# ESP32-S2 register map
Vendor: ESPRESSIF SYSTEMS (SHANGHAI) CO., LTD.; Series: ESP32 S-Series; File version: 20
CPU: Xtensa LX7 r0p0, little endian, no MPU, no FPU, 0 interrupt priority bits
Address unit: 32 bits
Registers are 32-bit, read-write, reset 0x0 unless marked. A register's access mark holds for its fields unless they carry their own. Offsets are from the block's base; [hi:lo] are bit positions; {n}, {i} and the like mark numbered series.

## SPI2 — SPI (Serial Peripheral Interface) Controller 2 (GPSPI)
Base 0x3F424000
Same registers: SPI3 0x3F425000, SPI4 0x3F437000
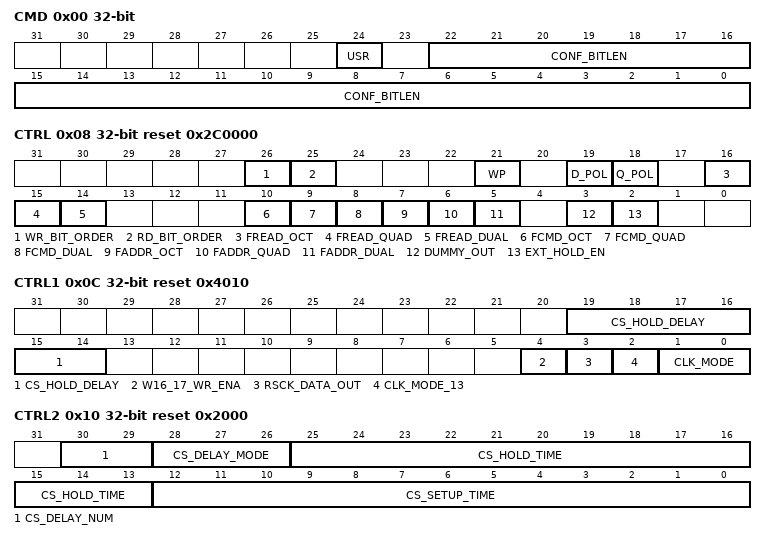
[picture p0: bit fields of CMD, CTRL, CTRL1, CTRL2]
0x00 CMD — Command control register
  [24] USR — User define command enable. An operation will be triggered when the bit is set. The bit will be cleared once the operation done.1: enable 0: disable. Can not be changed by CONF_buf.
  [22:0] CONF_BITLEN — Define the spi_clk cycles of SPI_CONF state. Can be configured in CONF state.
0x04 ADDR — Address value
  [31:0] USR_ADDR_VALUE — [31:8]:address to slave, [7:0]:Reserved. Can be configured in CONF state.
0x08 CTRL reset 0x2C0000 — SPI control register
  [26] WR_BIT_ORDER — In command address write-data (MOSI) phases 1: LSB firs 0: MSB first. Can be configured in CONF state.
  [25] RD_BIT_ORDER — In read-data (MISO) phase 1: LSB first 0: MSB first. Can be configured in CONF state.
  [21] WP — Write protect signal output when SPI is idle. 1: output high, 0: output low. Can be configured in CONF state.
  [19] D_POL — The bit is used to set MOSI line polarity, 1: high 0, low. Can be configured in CONF state.
  [18] Q_POL — The bit is used to set MISO line polarity, 1: high 0, low. Can be configured in CONF state.
  [16] FREAD_OCT — In the read operations read-data phase is in 8-bit mode. 1: enable 0: disable. Can be configured in CONF state.
  [15] FREAD_QUAD — In the read operations read-data phase is in 4-bit mode. 1: enable 0: disable. Can be configured in CONF state.
  [14] FREAD_DUAL — In the read operations, read-data phase is in 2-bit mode. 1: enable 0: disable. Can be configured in CONF state.
  [10] FCMD_OCT — Apply 8-bit mode during command phase 1:enable 0: disable. Can be configured in CONF state.
  [9] FCMD_QUAD — Apply 4-bit mode during command phase 1:enable 0: disable. Can be configured in CONF state.
  [8] FCMD_DUAL — Apply 2-bit mode during command phase 1:enable 0: disable. Can be configured in CONF state.
  [7] FADDR_OCT — Apply 8-bit mode during addr phase 1:enable 0: disable. Can be configured in CONF state.
  [6] FADDR_QUAD — Apply 4-bit mode during addr phase 1:enable 0: disable. Can be configured in CONF state.
  [5] FADDR_DUAL — Apply 2-bit mode during addr phase 1:enable 0: disable. Can be configured in CONF state.
  [3] DUMMY_OUT — In the dummy phase the signal level of spi is output by the spi controller. Can be configured in CONF state.
  [2] EXT_HOLD_EN — Set the bit to hold spi. The bit is combined with SPI_USR_PREP_HOLD,SPI_USR_CMD_HOLD,SPI_USR_ADDR_HOLD,SPI_USR_DUMMY_HOLD,SPI_USR_DIN_HOLD,SPI_USR_DOUT_HOLD and SPI_USR_HOLD_POL. Can be configured in CONF state.
0x0C CTRL1 reset 0x4010 — SPI control register 1
  [19:14] CS_HOLD_DELAY — SPI cs signal is delayed by spi clock cycles. Can be configured in CONF state.
  [4] W16_17_WR_ENA — 1:SPI_BUF16~SPI_BUF17 can be written 0:SPI_BUF16~SPI_BUF17 can not be written. Can be configured in CONF state.
  [3] RSCK_DATA_OUT — It saves half a cycle when tsck is the same as rsck. 1: output data at rsck posedge 0: output data at tsck posedge
  [2] CLK_MODE_13 — {CPOL, CPHA},1: support spi clk mode 1 and 3, first edge output data B[0]/B[7]. 0: support spi clk mode 0 and 2, first edge output data B[1]/B[6].
  [1:0] CLK_MODE — SPI clock mode bits. 0: SPI clock is off when CS inactive 1: SPI clock is delayed one cycle after CS inactive 2: SPI clock is delayed two cycles after CS inactive 3: SPI clock is alwasy on. Can be configured in CONF state.
0x10 CTRL2 reset 0x2000 — SPI control register 2
  [30:29] CS_DELAY_NUM — spi_cs signal is delayed by system clock cycles. Can be configured in CONF state.
  [28:26] CS_DELAY_MODE — spi_cs signal is delayed by spi_clk . 0: zero 1: if SPI_CK_OUT_EDGE or SPI_CK_IDLE_EDGE is set 1 delayed by half cycle else delayed by one cycle 2: if SPI_CK_OUT_EDGE or SPI_CK_IDLE_EDGE is set 1 delayed by one cycle, else delayed by half cycle 3: delayed one cycle. Can be configured in CONF state.
  [25:13] CS_HOLD_TIME — delay cycles of cs pin by spi clock this bits are combined with SPI_CS_HOLD bit. Can be configured in CONF state.
  [12:0] CS_SETUP_TIME — (cycles+1) of prepare phase by spi clock this bits are combined with SPI_CS_SETUP bit. Can be configured in CONF state.
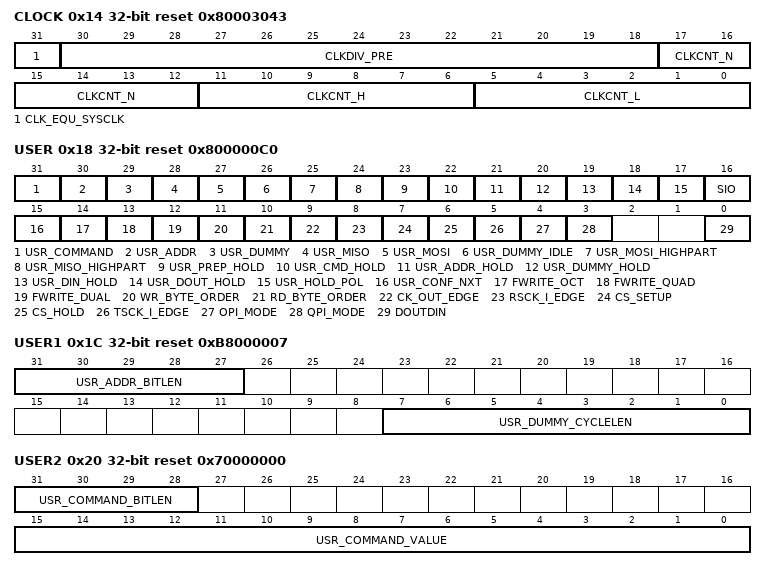
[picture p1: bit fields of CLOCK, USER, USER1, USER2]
0x14 CLOCK reset 0x80003043 — SPI clock control register
  [31] CLK_EQU_SYSCLK — In the master mode 1: spi_clk is eqaul to system 0: spi_clk is divided from system clock. Can be configured in CONF state.
  [30:18] CLKDIV_PRE — In the master mode it is pre-divider of spi_clk. Can be configured in CONF state.
  [17:12] CLKCNT_N — In the master mode it is the divider of spi_clk. So spi_clk frequency is system/(SPI_CLKDIV_PRE+1)/(SPI_CLKCNT_N+1). Can be configured in CONF state.
  [11:6] CLKCNT_H — In the master mode it must be floor((SPI_CLKCNT_N+1)/2-1). In the slave mode it must be 0. Can be configured in CONF state.
  [5:0] CLKCNT_L — In the master mode it must be equal to SPI_CLKCNT_N. In the slave mode it must be 0. Can be configured in CONF state.
0x18 USER reset 0x800000C0 — SPI USER control register
  [31] USR_COMMAND — This bit enable the command phase of an operation. Can be configured in CONF state.
  [30] USR_ADDR — This bit enable the address phase of an operation. Can be configured in CONF state.
  [29] USR_DUMMY — This bit enable the dummy phase of an operation. Can be configured in CONF state.
  [28] USR_MISO — This bit enable the read-data phase of an operation. Can be configured in CONF state.
  [27] USR_MOSI — This bit enable the write-data phase of an operation. Can be configured in CONF state.
  [26] USR_DUMMY_IDLE — spi clock is disable in dummy phase when the bit is enable. Can be configured in CONF state.
  [25] USR_MOSI_HIGHPART — write-data phase only access to high-part of the buffer SPI_BUF8~SPI_BUF17. 1: enable 0: disable. Can be configured in CONF state.
  [24] USR_MISO_HIGHPART — read-data phase only access to high-part of the buffer SPI_BUF8~SPI_BUF17. 1: enable 0: disable. Can be configured in CONF state.
  [23] USR_PREP_HOLD — spi is hold at prepare state the bit are combined with SPI_USR_HOLD_POL bit. Can be configured in CONF state.
  [22] USR_CMD_HOLD — spi is hold at command state the bit are combined with SPI_USR_HOLD_POL bit. Can be configured in CONF state.
  [21] USR_ADDR_HOLD — spi is hold at address state the bit are combined with SPI_USR_HOLD_POL bit. Can be configured in CONF state.
  [20] USR_DUMMY_HOLD — spi is hold at dummy state the bit are combined with SPI_USR_HOLD_POL bit. Can be configured in CONF state.
  [19] USR_DIN_HOLD — spi is hold at data in state the bit are combined with SPI_USR_HOLD_POL bit. Can be configured in CONF state.
  [18] USR_DOUT_HOLD — spi is hold at data out state the bit are combined with SPI_USR_HOLD_POL bit. Can be configured in CONF state.
  [17] USR_HOLD_POL — It is combined with hold bits to set the polarity of spi hold line 1: spi will be held when spi hold line is high 0: spi will be held when spi hold line is low. Can be configured in CONF state.
  [16] SIO — Set the bit to enable 3-line half duplex communication mosi and miso signals share the same pin. 1: enable 0: disable. Can be configured in CONF state.
  [15] USR_CONF_NXT — 1: Enable the DMA CONF phase of next seg-trans operation, which means seg-trans will continue. 0: The seg-trans will end after the current SPI seg-trans or this is not seg-trans mode. Can be configured in CONF state.
  [14] FWRITE_OCT — In the write operations read-data phase is in 8-bit mode. Can be configured in CONF state.
  [13] FWRITE_QUAD — In the write operations read-data phase is in 4-bit mode. Can be configured in CONF state.
  [12] FWRITE_DUAL — In the write operations read-data phase is in 2-bit mode. Can be configured in CONF state.
  [11] WR_BYTE_ORDER — In command address write-data (MOSI) phases 1: big-endian 0: litte_endian. Can be configured in CONF state.
  [10] RD_BYTE_ORDER — In read-data (MISO) phase 1: big-endian 0: little_endian. Can be configured in CONF state.
  [9] CK_OUT_EDGE — the bit combined with SPI_DOUT_MODE register to set mosi signal delay mode. Can be configured in CONF state.
  [8] RSCK_I_EDGE — In the slave mode, this bit can be used to change the polarity of rsck. 0: rsck = !spi_ck_i. 1:rsck = spi_ck_i.
  [7] CS_SETUP — spi cs is enable when spi is in prepare phase. 1: enable 0: disable. Can be configured in CONF state.
  [6] CS_HOLD — spi cs keep low when spi is in done phase. 1: enable 0: disable. Can be configured in CONF state.
  [5] TSCK_I_EDGE — In the slave mode, this bit can be used to change the polarity of tsck. 0: tsck = spi_ck_i. 1:tsck = !spi_ck_i.
  [4] OPI_MODE — Just for master mode. 1: spi controller is in OPI mode (all in 8-bit mode). 0: others. Can be configured in CONF state.
  [3] QPI_MODE — Both for master mode and slave mode. 1: spi controller is in QPI mode. 0: others. Can be configured in CONF state.
  [0] DOUTDIN — Set the bit to enable full duplex communication. 1: enable 0: disable. Can be configured in CONF state.
0x1C USER1 reset 0xB8000007 — SPI USER control register 1
  [31:27] USR_ADDR_BITLEN — The length in bits of address phase. The register value shall be (bit_num-1). Can be configured in CONF state.
  [7:0] USR_DUMMY_CYCLELEN — The length in spi_clk cycles of dummy phase. The register value shall be (cycle_num-1). Can be configured in CONF state.
0x20 USER2 reset 0x70000000 — SPI USER control register 2
  [31:28] USR_COMMAND_BITLEN — The length in bits of command phase. The register value shall be (bit_num-1). Can be configured in CONF state.
  [15:0] USR_COMMAND_VALUE — The value of command. Can be configured in CONF state.
0x24 MOSI_DLEN — MOSI length
  [22:0] USR_MOSI_DBITLEN — The length in bits of write-data. The register value shall be (bit_num-1). Can be configured in CONF state.
0x28 MISO_DLEN — MISO length
  [22:0] USR_MISO_DBITLEN — The length in bits of read-data. The register value shall be (bit_num-1). Can be configured in CONF state.
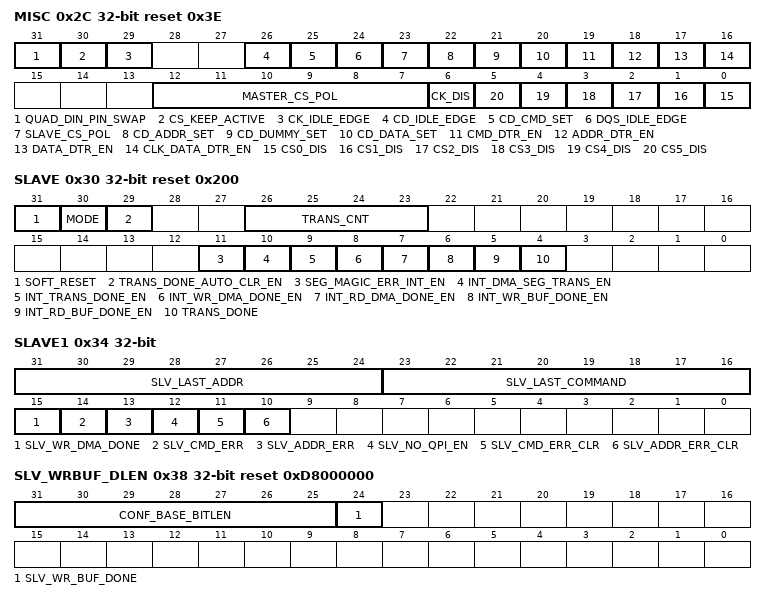
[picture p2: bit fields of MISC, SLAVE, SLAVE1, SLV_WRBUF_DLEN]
0x2C MISC reset 0x3E — SPI misc register
  [31] QUAD_DIN_PIN_SWAP — 1: spi quad input swap enable 0: spi quad input swap disable. Can be configured in CONF state.
  [30] CS_KEEP_ACTIVE — spi cs line keep low when the bit is set. Can be configured in CONF state.
  [29] CK_IDLE_EDGE — 1: spi clk line is high when idle 0: spi clk line is low when idle. Can be configured in CONF state.
  [26] CD_IDLE_EDGE — The default value of spi_cd. Can be configured in CONF state.
  [25] CD_CMD_SET — 1: spi_cd = !SPI_CD_IDLE_EDGE when SPI_ST[3:0] is in SPI_SEND_CMD state. 0: spi_cd = SPI_CD_IDLE_EDGE. Can be configured in CONF state.
  [24] DQS_IDLE_EDGE — The default value of spi_dqs. Can be configured in CONF state.
  [23] SLAVE_CS_POL — spi slave input cs polarity select. 1: inv 0: not change. Can be configured in CONF state.
  [22] CD_ADDR_SET — 1: spi_cd = !SPI_CD_IDLE_EDGE when SPI_ST[3:0] is in SPI_SEND_ADDR state. 0: spi_cd = SPI_CD_IDLE_EDGE. Can be configured in CONF state.
  [21] CD_DUMMY_SET — 1: spi_cd = !SPI_CD_IDLE_EDGE when SPI_ST[3:0] is in SPI_DUMMY state. 0: spi_cd = SPI_CD_IDLE_EDGE. Can be configured in CONF state.
  [20] CD_DATA_SET — 1: spi_cd = !SPI_CD_IDLE_EDGE when SPI_ST[3:0] is in SPI_DOUT or SPI_DIN state. 0: spi_cd = SPI_CD_IDLE_EDGE. Can be configured in CONF state.
  [19] CMD_DTR_EN — 1: SPI clk and data of SPI_SEND_CMD state are in DTR mode, including master 1/2/4/8-bm. 0: SPI clk and data of SPI_SEND_CMD state are in STR mode. Can be configured in CONF state.
  [18] ADDR_DTR_EN — 1: SPI clk and data of SPI_SEND_ADDR state are in DTR mode, including master 1/2/4/8-bm. 0: SPI clk and data of SPI_SEND_ADDR state are in STR mode. Can be configured in CONF state.
  [17] DATA_DTR_EN — 1: SPI clk and data of SPI_DOUT and SPI_DIN state are in DTR mode, including master 1/2/4/8-bm. 0: SPI clk and data of SPI_DOUT and SPI_DIN state are in STR mode. Can be configured in CONF state.
  [16] CLK_DATA_DTR_EN — 1: SPI master DTR mode is applied to SPI clk, data and spi_dqs. 0: SPI master DTR mode is only applied to spi_dqs. This bit should be used with bit 17/18/19.
  [12:7] MASTER_CS_POL — In the master mode the bits are the polarity of spi cs line, the value is equivalent to spi_cs ^ SPI_MASTER_CS_POL. Can be configured in CONF state.
  [6] CK_DIS — 1: spi clk out disable, 0: spi clk out enable. Can be configured in CONF state.
  [n] CS{n}_DIS (n=0..5) — Set this bit to raise high SPI_CS{n} pin, which means that the SPI device(Ext_RAM(0)/flash(1)) connected to SPI_CS{n} is in low level when SPI1 transfer starts
0x30 SLAVE access per field reset 0x200 — SPI slave control register
  [31] SOFT_RESET rw — Software reset enable, reset the spi clock line cs line and data lines. Can be configured in CONF state.
  [30] MODE rw — Set SPI work mode. 1: slave mode 0: master mode.
  [29] TRANS_DONE_AUTO_CLR_EN rw — SPI_TRANS_DONE auto clear enable, clear it 3 apb cycles after the pos edge of SPI_TRANS_DONE. 0:disable. 1: enable. Can be configured in CONF state.
  [26:23] TRANS_CNT ro — The operations counter in both the master mode and the slave mode.
  [11] SEG_MAGIC_ERR_INT_EN rw — 1: Enable seg magic value error interrupt. 0: Others. Can be configured in CONF state.
  [10] INT_DMA_SEG_TRANS_EN rw — SPI_DMA_SEG_TRANS_DONE Interrupt enable. 1: enable 0: disable. Can be configured in CONF state.
  [9] INT_TRANS_DONE_EN rw — SPI_TRANS_DONE Interrupt enable. 1: enable 0: disable. Can be configured in CONF state.
  [8] INT_WR_DMA_DONE_EN rw — SPI_SLV_WR_DMA_DONE Interrupt enable. 1: enable 0: disable. Can be configured in CONF state.
  [7] INT_RD_DMA_DONE_EN rw — SPI_SLV_RD_DMA_DONE Interrupt enable. 1: enable 0: disable. Can be configured in CONF state.
  [6] INT_WR_BUF_DONE_EN rw — SPI_SLV_WR_BUF_DONE Interrupt enable. 1: enable 0: disable. Can be configured in CONF state.
  [5] INT_RD_BUF_DONE_EN rw — SPI_SLV_RD_BUF_DONE Interrupt enable. 1: enable 0: disable. Can be configured in CONF state.
  [4] TRANS_DONE rw — The interrupt raw bit for the completion of any operation in both the master mode and the slave mode. Can not be changed by CONF_buf.
0x34 SLAVE1 access per field — SPI slave control register 1
  [31:24] SLV_LAST_ADDR rw — In the slave mode it is the value of address.
  [23:16] SLV_LAST_COMMAND rw — In the slave mode it is the value of command.
  [15] SLV_WR_DMA_DONE rw — The interrupt raw bit for the completion of dma write operation in the slave mode. Can not be changed by CONF_buf.
  [14] SLV_CMD_ERR ro — 1: The command value of the last SPI transfer is not supported by SPI slave. 0: The command value is supported or no command value is received.
  [13] SLV_ADDR_ERR ro — 1: The address value of the last SPI transfer is not supported by SPI slave. 0: The address value is supported or no address value is received.
  [12] SLV_NO_QPI_EN rw — 1: spi slave QPI mode is not supported. 0: spi slave QPI mode is supported.
  [11] SLV_CMD_ERR_CLR rw — 1: Clear SPI_SLV_CMD_ERR. 0: not valid. Can be changed by CONF_buf.
  [10] SLV_ADDR_ERR_CLR rw — 1: Clear SPI_SLV_ADDR_ERR. 0: not valid. Can be changed by CONF_buf.
0x38 SLV_WRBUF_DLEN reset 0xD8000000 — SPI slave Wr_BUF interrupt and CONF control register
  [31:25] CONF_BASE_BITLEN — The basic spi_clk cycles of CONF state. The real cycle length of CONF state, if SPI_USR_CONF is enabled, is SPI_CONF_BASE_BITLEN[6:0] + SPI_CONF_BITLEN[23:0].
  [24] SLV_WR_BUF_DONE — The interrupt raw bit for the completion of write-buffer operation in the slave mode. Can not be changed by CONF_buf.
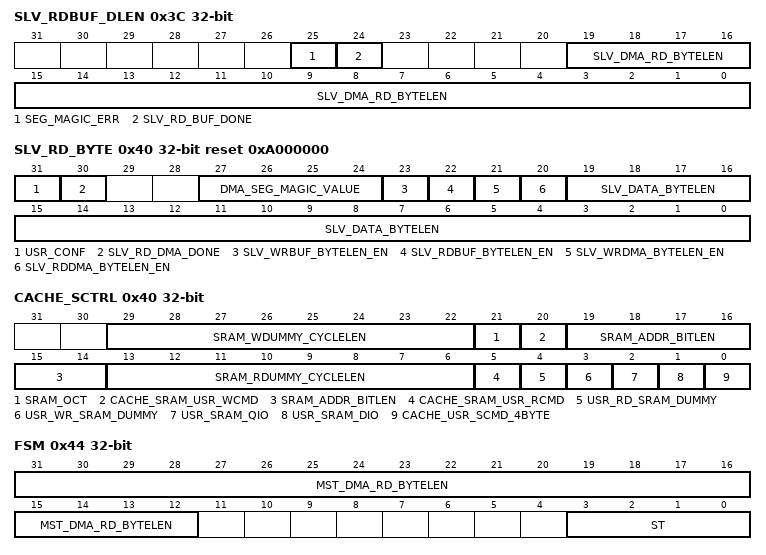
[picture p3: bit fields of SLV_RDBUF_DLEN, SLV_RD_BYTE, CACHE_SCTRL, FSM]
0x3C SLV_RDBUF_DLEN — SPI magic error and slave control register
  [25] SEG_MAGIC_ERR — 1: The recent magic value in CONF buffer is not right in master DMA seg-trans mode. 0: others.
  [24] SLV_RD_BUF_DONE — The interrupt raw bit for the completion of read-buffer operation in the slave mode. Can not be changed by CONF_buf.
  [19:0] SLV_DMA_RD_BYTELEN — In the slave mode it is the length in bytes for read operations. The register value shall be byte_num.
0x40 SLV_RD_BYTE reset 0xA000000 — SPI interrupt control register
  [31] USR_CONF — 1: Enable the DMA CONF phase of current seg-trans operation, which means seg-trans will start. 0: This is not seg-trans mode.
  [30] SLV_RD_DMA_DONE — The interrupt raw bit for the completion of Rd-DMA operation in the slave mode. Can not be changed by CONF_buf.
  [27:24] DMA_SEG_MAGIC_VALUE — The magic value of BM table in master DMA seg-trans.
  [23] SLV_WRBUF_BYTELEN_EN — 1: SPI_SLV_DATA_BYTELEN stores data byte length of master-write-to-slave data length in CPU controlled mode(Wr_BUF). 0: others
  [22] SLV_RDBUF_BYTELEN_EN — 1: SPI_SLV_DATA_BYTELEN stores data byte length of master-read-slave data length in CPU controlled mode(Rd_BUF). 0: others
  [21] SLV_WRDMA_BYTELEN_EN — 1: SPI_SLV_DATA_BYTELEN stores data byte length of master-write-to-slave data length in DMA controlled mode(Wr_DMA). 0: others
  [20] SLV_RDDMA_BYTELEN_EN — 1: SPI_SLV_DATA_BYTELEN stores data byte length of master-read-slave data length in DMA controlled mode(Rd_DMA). 0: others
  [19:0] SLV_DATA_BYTELEN — The full-duplex or half-duplex data byte length of the last SPI transfer in slave mode. In half-duplex mode, this value is controlled by bits [23:20].
0x40 CACHE_SCTRL — SPI Memory Cache SCTRL Register
  [29:22] SRAM_WDUMMY_CYCLELEN — For SPI0, in the SRAM mode, it is the length in bits of write dummy phase. The register value shall be (bit_num-1).
  [21] SRAM_OCT — Reserved
  [20] CACHE_SRAM_USR_WCMD — For SPI0, in the SPI SRAM mode, cache write SRAM for user define command.
  [19:14] SRAM_ADDR_BITLEN — For SPI0, in the SRAM mode, it is the length in bits of address phase. The register value shall be (bit_num-1).
  [13:6] SRAM_RDUMMY_CYCLELEN — For SPI0, in the SRAM mode, it is the length in bits of read dummy phase. The register value shall be (bit_num-1).
  [5] CACHE_SRAM_USR_RCMD — For SPI0, in the SPI SRAM mode, cache read SRAM for user define command.
  [4] USR_RD_SRAM_DUMMY — For SPI0, in the SPI SRAM mode, it is the enable bit of dummy phase for read operations.
  [3] USR_WR_SRAM_DUMMY — For SPI0, in the SPI SRAM mode, it is the enable bit of dummy phase for write operations.
  [2] USR_SRAM_QIO — For SPI0, in the SPI SRAM mode, SPI quad I/O mode enable. 1: enable, 0: disable.
  [1] USR_SRAM_DIO — For SPI0, in the SPI SRAM mode, SPI dual I/O mode enable. 1: enable, 0: disable.
  [0] CACHE_USR_SCMD_4BYTE — For SPI0, in the SPI SRAM mode, cache read flash with 4 bytes command. 1: enable, 0: disable.
0x44 FSM access per field — SPI master status and DMA read byte control register
  [31:12] MST_DMA_RD_BYTELEN rw — Define the master DMA read byte length in non seg-conf-trans or seg-conf-trans mode. Invalid when SPI_RX_EOF_EN is 0. Can be configured in CONF state..
  [3:0] ST ro — The status of spi state machine. 0: idle state, 1: preparation state, 2: send command state, 3: send data state, 4: red data state, 5:write data state, 6: wait state, 7: done state.
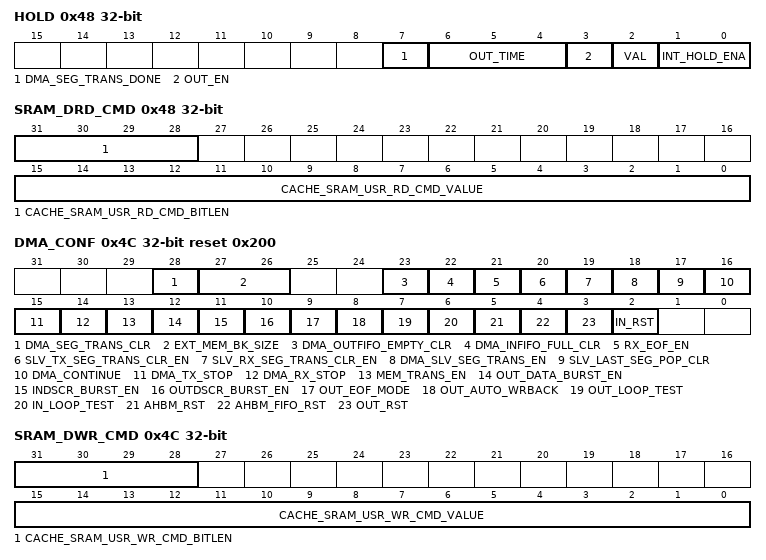
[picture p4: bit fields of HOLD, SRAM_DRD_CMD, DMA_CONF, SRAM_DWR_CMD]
0x48 HOLD — SPI hold register
  [7] DMA_SEG_TRANS_DONE — 1: spi master DMA full-duplex/half-duplex seg-trans ends or slave half-duplex seg-trans ends. And data has been pushed to corresponding memory. 0: seg-trans is not ended or not occurred. Can not be changed by CONF_buf.
  [6:4] OUT_TIME — set the hold cycles of output spi_hold signal when SPI_HOLD_OUT_EN is enable. Can be configured in CONF state.
  [3] OUT_EN — Enable set spi output hold value to spi_hold_reg. It can be used to hold spi state machine with SPI_EXT_HOLD_EN and other usr hold signals. Can be configured in CONF state.
  [2] VAL — spi hold output value, which should be used with SPI_HOLD_OUT_EN. Can be configured in CONF state.
  [1:0] INT_HOLD_ENA — This register is for two SPI masters to share the same cs clock and data signals. The bits of one SPI are set, if the other SPI is busy, the SPI will be hold. 1(3): hold at idle phase 2: hold at prepare phase. Can be configured in CONF state.
0x48 SRAM_DRD_CMD — SPI Memory SRAM DRD CMD Register
  [31:28] CACHE_SRAM_USR_RD_CMD_BITLEN — For SPI0, when cache mode is enabled, it is the length in bits of the command phase for SRAM. The register value shall be (bit_num-1).
  [15:0] CACHE_SRAM_USR_RD_CMD_VALUE — For SPI0, when cache mode is enabled, it is the read command value of the command phase for SRAM.
0x4C DMA_CONF reset 0x200 — SPI DMA control register
  [28] DMA_SEG_TRANS_CLR — 1: End slave seg-trans, which acts as 0x05 command. 2 or more end seg-trans signals will induce error in DMA RX. 0: others. Will be cleared in 1 APB CLK cycles by hardware..
  [27:26] EXT_MEM_BK_SIZE — Select the external memory block size.
  [23] DMA_OUTFIFO_EMPTY_CLR — 1:Clear spi_dma_outfifo_empty_vld. 0: Do not control it.
  [22] DMA_INFIFO_FULL_CLR — 1:Clear spi_dma_infifo_full_vld. 0: Do not control it.
  [21] RX_EOF_EN — 1: SPI_IN_SUC_EOF_INT_RAW is set when the number of dma pushed data bytes is equal to the value of SPI_SLV_DMA_RD_BYTELEN[19:0]/ SPI_MST_DMA_RD_BYTELEN[19:0] in spi dma transition. 0: SPI_IN_SUC_EOF_INT_RAW is set by SPI_TRANS_DONE in non-seg-trans or SPI_DMA_SEG_TRANS_DONE in seg-trans.
  [20] SLV_TX_SEG_TRANS_CLR_EN — 1: spi_dma_outfifo_empty_vld is cleared by spi slave CMD6. 0: spi_dma_outfifo_empty_vld is cleared by SPI_TRANS_DONE.
  [19] SLV_RX_SEG_TRANS_CLR_EN — 1: spi_dma_infifo_full_vld is cleared by spi slave CMD5. 0: spi_dma_infifo_full_vld is cleared by SPI_TRANS_DONE.
  [18] DMA_SLV_SEG_TRANS_EN — Enable dma segment transfer in spi dma half slave mode. 1: enable. 0: disable.
  [17] SLV_LAST_SEG_POP_CLR — 1: Clear spi_slv_seg_frt_pop_mask. 0 : others
  [16] DMA_CONTINUE — spi dma continue tx/rx data.
  [15] DMA_TX_STOP — spi dma write data stop when in continue tx/rx mode.
  [14] DMA_RX_STOP — spi dma read data stop when in continue tx/rx mode.
  [13] MEM_TRANS_EN — 1: Internal memory data transfer enable bit. Send SPI DMA RX buffer data to SPI DMA TX buffer. 0: Disable this function.
  [12] OUT_DATA_BURST_EN — spi dma read data from memory in burst mode.
  [11] INDSCR_BURST_EN — read descriptor use burst mode when write data to memory.
  [10] OUTDSCR_BURST_EN — read descriptor use burst mode when read data for memory.
  [9] OUT_EOF_MODE — out eof flag generation mode . 1: when dma pop all data from fifo 0:when ahb push all data to fifo.
  [8] OUT_AUTO_WRBACK — when the bit is set, DMA continue to use the next inlink node when the length of inlink is 0.
  [7] OUT_LOOP_TEST — Set bit to test out link.
  [6] IN_LOOP_TEST — Set bit to test in link.
  [5] AHBM_RST — Reset spi dma ahb master.
  [4] AHBM_FIFO_RST — Reset spi dma ahb master fifo pointer.
  [3] OUT_RST — The bit is used to reset out dma fsm and out data fifo pointer.
  [2] IN_RST — The bit is used to reset in dma fsm and in data fifo pointer.
0x4C SRAM_DWR_CMD — SPI Memory SRAM DWR CMD Register
  [31:28] CACHE_SRAM_USR_WR_CMD_BITLEN — For SPI0, when cache mode is enabled, it is the length in bits of the command phase for SRAM. The register value shall be (bit_num-1).
  [15:0] CACHE_SRAM_USR_WR_CMD_VALUE — For SPI0, when cache mode is enabled, it is the write command value of the command phase for SRAM.
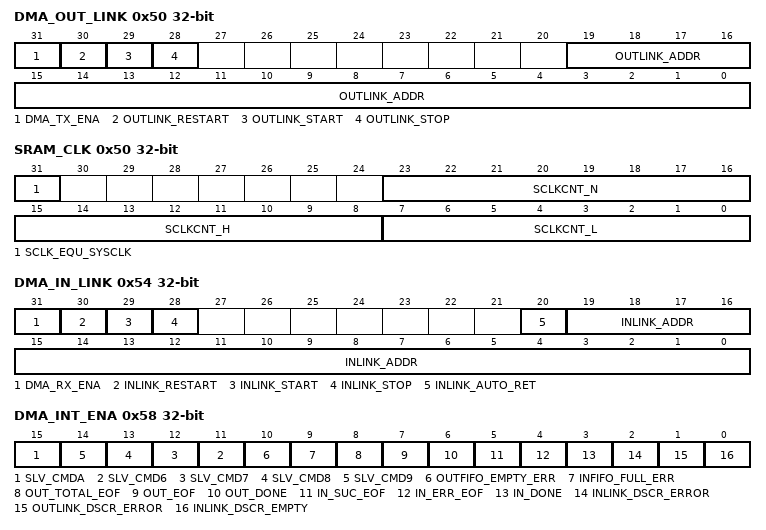
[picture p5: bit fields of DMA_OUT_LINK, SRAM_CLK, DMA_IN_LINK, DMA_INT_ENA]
0x50 DMA_OUT_LINK — SPI DMA TX link configuration
  [31] DMA_TX_ENA — spi dma write data status bit.
  [30] OUTLINK_RESTART — Set the bit to mount on new outlink descriptors.
  [29] OUTLINK_START — Set the bit to start to use outlink descriptor.
  [28] OUTLINK_STOP — Set the bit to stop to use outlink descriptor.
  [19:0] OUTLINK_ADDR — The address of the first outlink descriptor.
0x50 SRAM_CLK — SPI Memory SRAM Clock Register
  [31] SCLK_EQU_SYSCLK — For SPI0 SRAM interface, 1: spi_mem_clk is equal to system, 0: spi_mem_clk is divided from system clock.
  [23:16] SCLKCNT_N — For SPI0 SRAM interface, it is the divider of spi_mem_clk. So spi_mem_clk frequency is system/(spi_mem_clkcnt_N+1).
  [15:8] SCLKCNT_H — For SPI0 SRAM interface, it must be floor((spi_mem_clkcnt_N+1)/2-1).
  [7:0] SCLKCNT_L — For SPI0 SRAM interface, it must be equal to spi_mem_clkcnt_N.
0x54 DMA_IN_LINK — SPI DMA RX link configuration
  [31] DMA_RX_ENA — SPI DMA read data status bit.
  [30] INLINK_RESTART — Set the bit to mount on new inlink descriptors.
  [29] INLINK_START — Set the bit to start to use inlink descriptor.
  [28] INLINK_STOP — Set the bit to stop to use inlink descriptor.
  [20] INLINK_AUTO_RET — when the bit is set, the inlink descriptor returns to the first link node when a packet is error.
  [19:0] INLINK_ADDR — The address of the first inlink descriptor.
0x58 DMA_INT_ENA — SPI DMA interrupt enable register
  [15] SLV_CMDA — The enable bit for SPI slave CMDA interrupt.
  [n+5] SLV_CMD{n} (n=6..9) — The enable bit for SPI slave CMD{n} interrupt.
  [10] OUTFIFO_EMPTY_ERR — The enable bit for outfifo empty error interrupt.
  [9] INFIFO_FULL_ERR — The enable bit for infifo full error interrupt.
  [8] OUT_TOTAL_EOF — The enable bit for sending all the packets to host done. Can be configured in CONF state.
  [7] OUT_EOF — The enable bit for sending a packet to host done. Can be configured in CONF state.
  [6] OUT_DONE — The enable bit for completing usage of a outlink descriptor . Can be configured in CONF state.
  [5] IN_SUC_EOF — The enable bit for completing receiving all the packets from host. Can be configured in CONF state.
  [4] IN_ERR_EOF — The enable bit for receiving error. Can be configured in CONF state.
  [3] IN_DONE — The enable bit for completing usage of a inlink descriptor. Can be configured in CONF state.
  [2] INLINK_DSCR_ERROR — The enable bit for inlink descriptor error. Can be configured in CONF state.
  [1] OUTLINK_DSCR_ERROR — The enable bit for outlink descriptor error. Can be configured in CONF state.
  [0] INLINK_DSCR_EMPTY — The enable bit for lack of enough inlink descriptors. Can be configured in CONF state.
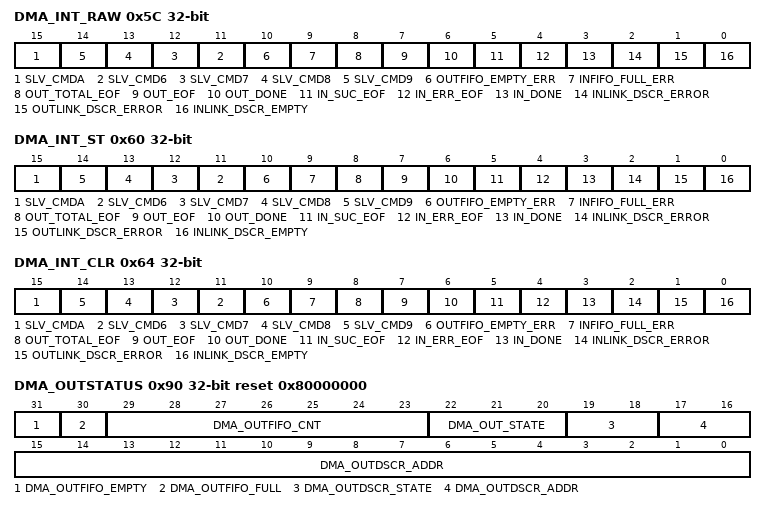
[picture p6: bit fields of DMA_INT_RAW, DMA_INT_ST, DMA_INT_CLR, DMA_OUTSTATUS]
0x5C DMA_INT_RAW access per field — SPI DMA interrupt raw register
  [15] SLV_CMDA rw — The raw bit for SPI slave CMDA interrupt.
  [n+5] SLV_CMD{n} rw (n=6..9) — The raw bit for SPI slave CMD{n} interrupt.
  [10] OUTFIFO_EMPTY_ERR ro — 1:SPI_DMA_OUTFIFO_EMPTY and spi_pop_data_prep are valid, which means that there is no data to pop but pop is valid. 0: Others. Can not be changed by CONF_buf.
  [9] INFIFO_FULL_ERR ro — 1:SPI_DMA_INFIFO_FULL and spi_push_data_prep are valid, which means that DMA Rx buffer is full but push is valid. 0: Others. Can not be changed by CONF_buf.
  [8] OUT_TOTAL_EOF ro — The raw bit for sending all the packets to host done. Can be configured in CONF state.
  [7] OUT_EOF ro — The raw bit for sending a packet to host done. Can be configured in CONF state.
  [6] OUT_DONE ro — The raw bit for completing usage of a outlink descriptor. Can be configured in CONF state.
  [5] IN_SUC_EOF ro — The raw bit for completing receiving all the packets from host. Can be configured in CONF state.
  [4] IN_ERR_EOF ro — The raw bit for receiving error. Can be configured in CONF state.
  [3] IN_DONE ro — The raw bit for completing usage of a inlink descriptor. Can be configured in CONF state.
  [2] INLINK_DSCR_ERROR ro — The raw bit for inlink descriptor error. Can be configured in CONF state.
  [1] OUTLINK_DSCR_ERROR ro — The raw bit for outlink descriptor error. Can be configured in CONF state.
  [0] INLINK_DSCR_EMPTY ro — The raw bit for lack of enough inlink descriptors. Can be configured in CONF state.
0x60 DMA_INT_ST access per field — SPI DMA interrupt status register
  [15] SLV_CMDA rw — The status bit for SPI slave CMDA interrupt.
  [n+5] SLV_CMD{n} rw (n=6..9) — The status bit for SPI slave CMD{n} interrupt.
  [10] OUTFIFO_EMPTY_ERR ro — The status bit for outfifo empty error.
  [9] INFIFO_FULL_ERR ro — The status bit for infifo full error.
  [8] OUT_TOTAL_EOF ro — The status bit for sending all the packets to host done.
  [7] OUT_EOF ro — The status bit for sending a packet to host done.
  [6] OUT_DONE ro — The status bit for completing usage of a outlink descriptor.
  [5] IN_SUC_EOF ro — The status bit for completing receiving all the packets from host.
  [4] IN_ERR_EOF ro — The status bit for receiving error.
  [3] IN_DONE ro — The status bit for completing usage of a inlink descriptor.
  [2] INLINK_DSCR_ERROR ro — The status bit for inlink descriptor error.
  [1] OUTLINK_DSCR_ERROR ro — The status bit for outlink descriptor error.
  [0] INLINK_DSCR_EMPTY ro — The status bit for lack of enough inlink descriptors.
0x64 DMA_INT_CLR — SPI DMA interrupt clear register
  [15] SLV_CMDA write-1-clears — The clear bit for SPI slave CMDA interrupt.
  [n+5] SLV_CMD{n} write-1-clears (n=6..9) — The clear bit for SPI slave CMD{n} interrupt.
  [10] OUTFIFO_EMPTY_ERR write-1-clears — 1: Clear SPI_OUTFIFO_EMPTY_ERR_INT_RAW signal. 0: not valid. Can be changed by CONF_buf.
  [9] INFIFO_FULL_ERR write-1-clears — 1: Clear SPI_INFIFO_FULL_ERR_INT_RAW. 0: not valid. Can be changed by CONF_buf.
  [8] OUT_TOTAL_EOF write-1-clears — The clear bit for sending all the packets to host done. Can be configured in CONF state.
  [7] OUT_EOF write-1-clears — The clear bit for sending a packet to host done. Can be configured in CONF state.
  [6] OUT_DONE write-1-clears — The clear bit for completing usage of a outlink descriptor. Can be configured in CONF state.
  [5] IN_SUC_EOF write-1-clears — The clear bit for completing receiving all the packets from host. Can be configured in CONF state.
  [4] IN_ERR_EOF write-1-clears — The clear bit for receiving error. Can be configured in CONF state.
  [3] IN_DONE write-1-clears — The clear bit for completing usage of a inlink descriptor. Can be configured in CONF state.
  [2] INLINK_DSCR_ERROR write-1-clears — The clear bit for inlink descriptor error. Can be configured in CONF state.
  [1] OUTLINK_DSCR_ERROR write-1-clears — The clear bit for outlink descriptor error. Can be configured in CONF state.
  [0] INLINK_DSCR_EMPTY write-1-clears — The clear bit for lack of enough inlink descriptors. Can be configured in CONF state.
0x68 IN_ERR_EOF_DES_ADDR ro — The latest SPI DMA RX descriptor address receiving error
  [31:0] DMA_IN_ERR_EOF_DES_ADDR — The inlink descriptor address when spi dma produce receiving error.
0x6C IN_SUC_EOF_DES_ADDR ro — The latest SPI DMA eof RX descriptor address
  [31:0] DMA_IN_SUC_EOF_DES_ADDR — The last inlink descriptor address when spi dma produce from_suc_eof.
0x70 INLINK_DSCR ro — Current SPI DMA RX descriptor pointer
  [31:0] DMA_INLINK_DSCR — The content of current in descriptor pointer.
0x74 INLINK_DSCR_BF0 ro — Next SPI DMA RX descriptor pointer
  [31:0] DMA_INLINK_DSCR_BF0 — The content of next in descriptor pointer.
0x78 INLINK_DSCR_BF1 ro — Current SPI DMA RX buffer pointer
  [31:0] DMA_INLINK_DSCR_BF1 — The content of current in descriptor data buffer pointer.
0x7C OUT_EOF_BFR_DES_ADDR ro — The latest SPI DMA eof TX buffer address
  [31:0] DMA_OUT_EOF_BFR_DES_ADDR — The address of buffer relative to the outlink descriptor that produce eof.
0x80 OUT_EOF_DES_ADDR ro — The latest SPI DMA eof TX descriptor address
  [31:0] DMA_OUT_EOF_DES_ADDR — The last outlink descriptor address when spi dma produce to_eof.
0x84 OUTLINK_DSCR ro — Current SPI DMA TX descriptor pointer
  [31:0] DMA_OUTLINK_DSCR — The content of current out descriptor pointer.
0x88 OUTLINK_DSCR_BF0 ro — Next SPI DMA TX descriptor pointer
  [31:0] DMA_OUTLINK_DSCR_BF0 — The content of next out descriptor pointer.
0x8C OUTLINK_DSCR_BF1 ro — Current SPI DMA TX buffer pointer
  [31:0] DMA_OUTLINK_DSCR_BF1 — The content of current out descriptor data buffer pointer.
0x90 DMA_OUTSTATUS ro reset 0x80000000 — SPI DMA TX status
  [31] DMA_OUTFIFO_EMPTY — SPI dma outfifo is empty.
  [30] DMA_OUTFIFO_FULL — SPI dma outfifo is full.
  [29:23] DMA_OUTFIFO_CNT — The remains of SPI dma outfifo data.
  [22:20] DMA_OUT_STATE — SPI dma out data state.
  [19:18] DMA_OUTDSCR_STATE — SPI dma out descriptor state.
  [17:0] DMA_OUTDSCR_ADDR — SPI dma out descriptor address.
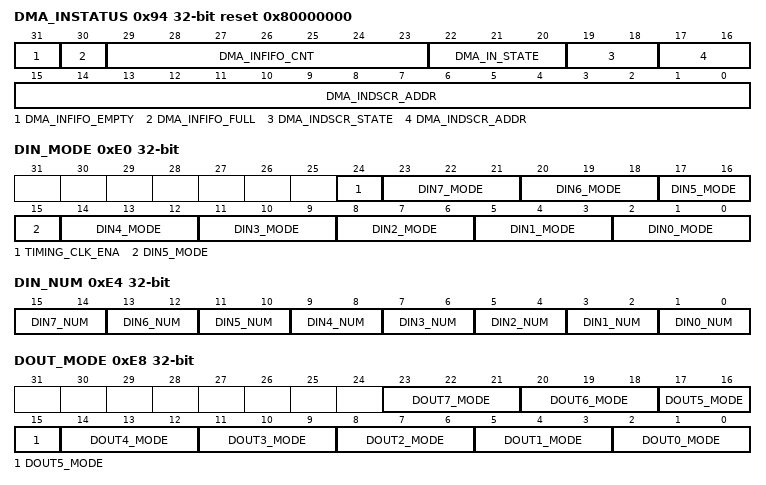
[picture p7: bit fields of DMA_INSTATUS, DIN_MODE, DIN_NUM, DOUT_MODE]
0x94 DMA_INSTATUS ro reset 0x80000000 — SPI DMA RX status
  [31] DMA_INFIFO_EMPTY — SPI dma infifo is empty.
  [30] DMA_INFIFO_FULL — SPI dma infifo is full.
  [29:23] DMA_INFIFO_CNT — The remains of SPI dma infifo data.
  [22:20] DMA_IN_STATE — SPI dma in data state.
  [19:18] DMA_INDSCR_STATE — SPI dma in descriptor state.
  [17:0] DMA_INDSCR_ADDR — SPI dma in descriptor address.
{0x98+4i} W{i} (i=0..17) — Data buffer {i}
  [31:0] BUF — 32 bits data buffer 0, transferred in the unit of byte. Byte addressable in slave half-duplex mode.
0xDC CLOCK_GATE — SPI Memory Clock Gate Register
  [0] CLK_EN — Register clock gate enable signal. 1: Enable. 0. Disable.
0xE0 DIN_MODE — SPI input delay mode configuration
  [24] TIMING_CLK_ENA — 1:enable hclk in spi_timing.v. 0: disable it. Can be configured in CONF state.
  [3n+2:3n] DIN{n}_MODE (n=0..7) — the input signals are delayed by system clock cycles, 0: input without delayed, 1: input with the posedge of clk_apb,2 input with the negedge of clk_apb, 3: input with the spi_clk. Can be configured in CONF state.
0xE4 DIN_NUM — SPI input delay number configuration
  [2n+1:2n] DIN{n}_NUM (n=0..7) — the input signals are delayed by system clock cycles, 0: delayed by 1 cycle, 1: delayed by 2 cycles,... Can be configured in CONF state.
0xE8 DOUT_MODE — SPI output delay mode configuration
  [3n+2:3n] DOUT{n}_MODE (n=0..7) — the output signals are delayed by system clock cycles, 0: output without delayed, 1: output with the posedge of clk_apb,2 output with the negedge of clk_apb, 3: output with the spi_clk. Can be configured in CONF state.
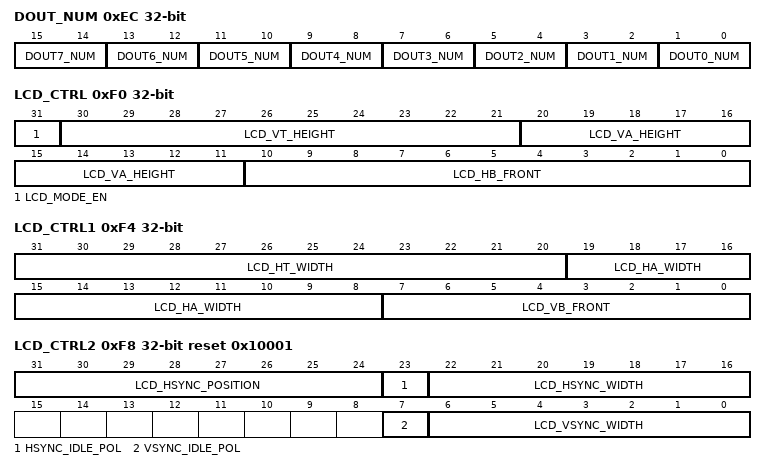
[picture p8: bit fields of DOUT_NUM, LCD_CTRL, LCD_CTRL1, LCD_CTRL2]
0xEC DOUT_NUM — SPI output delay number configuration
  [2n+1:2n] DOUT{n}_NUM (n=0..7) — the output signals are delayed by system clock cycles, 0: delayed by 1 cycle, 1: delayed by 2 cycles,... Can be configured in CONF state.
0xF0 LCD_CTRL — LCD frame control register
  [31] LCD_MODE_EN — 1: Enable LCD mode output vsync, hsync, de. 0: Disable. Can be configured in CONF state.
  [30:21] LCD_VT_HEIGHT — It is the vertical total height of a frame. Can be configured in CONF state.
  [20:11] LCD_VA_HEIGHT — It is the vertical active height of a frame. Can be configured in CONF state.
  [10:0] LCD_HB_FRONT — It is the horizontal blank front porch of a frame. Can be configured in CONF state.
0xF4 LCD_CTRL1 — LCD frame control1 register
  [31:20] LCD_HT_WIDTH — It is the horizontal total width of a frame. Can be configured in CONF state.
  [19:8] LCD_HA_WIDTH — It is the horizontal active width of a frame. Can be configured in CONF state.
  [7:0] LCD_VB_FRONT — It is the vertical blank front porch of a frame. Can be configured in CONF state.
0xF8 LCD_CTRL2 reset 0x10001 — LCD frame control2 register
  [31:24] LCD_HSYNC_POSITION — It is the position of spi_hsync active pulse in a line. Can be configured in CONF state.
  [23] HSYNC_IDLE_POL — It is the idle value of spi_hsync. Can be configured in CONF state.
  [22:16] LCD_HSYNC_WIDTH — It is the position of spi_hsync active pulse in a line. Can be configured in CONF state.
  [7] VSYNC_IDLE_POL — It is the idle value of spi_vsync. Can be configured in CONF state.
  [6:0] LCD_VSYNC_WIDTH — It is the position of spi_vsync active pulse in a line. Can be configured in CONF state.
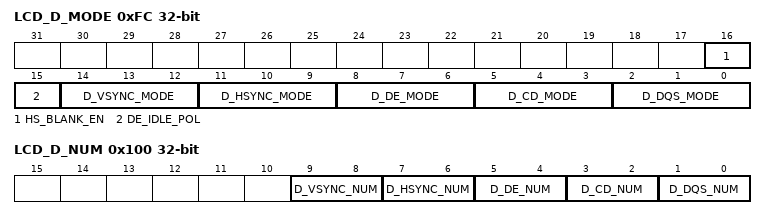
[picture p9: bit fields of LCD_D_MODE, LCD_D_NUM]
0xFC LCD_D_MODE — LCD delay number
  [16] HS_BLANK_EN — 1: The pulse of spi_hsync is out in vertical blanking lines in seg-trans or one trans. 0: spi_hsync pulse is valid only in active region lines in seg-trans.
  [15] DE_IDLE_POL — It is the idle value of spi_de.
  [14:12] D_VSYNC_MODE — the output spi_vsync is delayed by system clock cycles, 0: output without delayed, 1: output with the posedge of clk_apb,2 output with the negedge of clk_apb, 3: output with the spi_clk. Can be configured in CONF state.
  [11:9] D_HSYNC_MODE — the output spi_hsync is delayed by system clock cycles, 0: output without delayed, 1: output with the posedge of clk_apb,2 output with the negedge of clk_apb, 3: output with the spi_clk. Can be configured in CONF state.
  [8:6] D_DE_MODE — the output spi_de is delayed by system clock cycles, 0: output without delayed, 1: output with the posedge of clk_apb,2 output with the negedge of clk_apb, 3: output with the spi_clk. Can be configured in CONF state.
  [5:3] D_CD_MODE — the output spi_cd is delayed by system clock cycles, 0: output without delayed, 1: output with the posedge of clk_apb,2 output with the negedge of clk_apb, 3: output with the spi_clk. Can be configured in CONF state.
  [2:0] D_DQS_MODE — the output spi_dqs is delayed by system clock cycles, 0: output without delayed, 1: output with the posedge of clk_apb,2 output with the negedge of clk_apb, 3: output with the spi_clk. Can be configured in CONF state.
0x100 LCD_D_NUM — LCD delay mode
  [9:8] D_VSYNC_NUM — the output spi_vsync is delayed by system clock cycles, 0: delayed by 1 cycle, 1: delayed by 2 cycles,... Can be configured in CONF state.
  [7:6] D_HSYNC_NUM — the output spi_hsync is delayed by system clock cycles, 0: delayed by 1 cycle, 1: delayed by 2 cycles,... Can be configured in CONF state.
  [5:4] D_DE_NUM — the output spi_de is delayed by system clock cycles, 0: delayed by 1 cycle, 1: delayed by 2 cycles,... Can be configured in CONF state.
  [3:2] D_CD_NUM — the output spi_cd is delayed by system clock cycles, 0: delayed by 1 cycle, 1: delayed by 2 cycles,... Can be configured in CONF state.
  [1:0] D_DQS_NUM — the output spi_dqs is delayed by system clock cycles, 0: delayed by 1 cycle, 1: delayed by 2 cycles,... Can be configured in CONF state.
0x3FC REG_DATE — SPI version control
